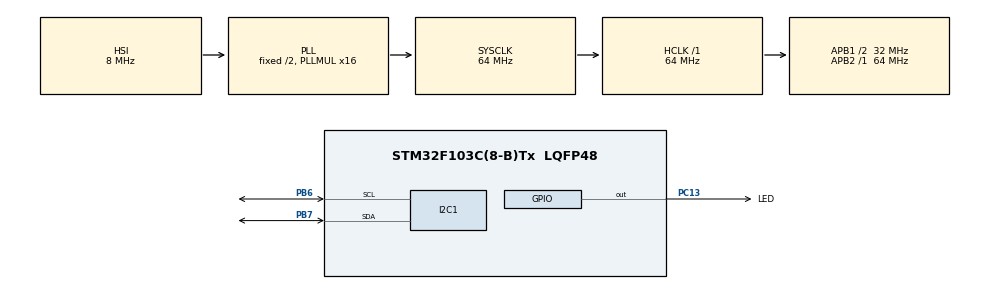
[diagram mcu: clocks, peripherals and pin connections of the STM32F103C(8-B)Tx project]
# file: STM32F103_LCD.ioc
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Mcu.Family=STM32F1
Mcu.Name=STM32F103C(8-B)Tx
Mcu.Package=LQFP48
NVIC.PriorityGroup=NVIC_PRIORITYGROUP_4
PA13.Mode=Trace_Asynchronous_SW
PA13.Signal=SYS_JTMS-SWDIO
PA14.Mode=Trace_Asynchronous_SW
PA14.Signal=SYS_JTCK-SWCLK
PB3.Mode=Trace_Asynchronous_SW
PB3.Signal=SYS_JTDO-TRACESWO
PB6.Mode=I2C
PB6.Signal=I2C1_SCL
PB7.Mode=I2C
PB7.Signal=I2C1_SDA
PC13-TAMPER-RTC.GPIO_Label=LED
PC13-TAMPER-RTC.Signal=GPIO_Output
ProjectManager.HeapSize=0x200
ProjectManager.StackSize=0x400
ProjectManager.TargetToolchain=STM32CubeIDE
RCC.AHBFreq_Value=64000000
RCC.APB1CLKDivider=RCC_HCLK_DIV2
RCC.APB1Freq_Value=32000000
RCC.APB1TimFreq_Value=64000000
RCC.APB2Freq_Value=64000000
RCC.APB2TimFreq_Value=64000000
RCC.HCLKFreq_Value=64000000
RCC.PLLMUL=RCC_PLL_MUL16
RCC.SYSCLKFreq_VALUE=64000000
RCC.SYSCLKSource=RCC_SYSCLKSOURCE_PLLCLK
RCC.USBFreq_Value=64000000
TIM3.Period=0xFFFF
TIM3.Prescaler=63
VP_TIM3_VS_ClockSourceINT.Mode=Internal
board=custom

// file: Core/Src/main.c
/* USER CODE BEGIN Header */
/**
  ******************************************************************************
  * @file           : main.c
  * @brief          : Main program body
  ******************************************************************************
  * @attention
  *
  * <h2><center>&copy; Copyright (c) 2021 STMicroelectronics.
  * All rights reserved.</center></h2>
  *
  * This software component is licensed by ST under BSD 3-Clause license,
  * the "License"; You may not use this file except in compliance with the
  * License. You may obtain a copy of the License at:
  *                        opensource.org/licenses/BSD-3-Clause
  *
  ******************************************************************************
  */
/* USER CODE END Header */
#include "main.h"
#include "i2c.h"
#include "tim.h"
#include "gpio.h"

/* USER CODE BEGIN Includes */
#include "LCD_HD44780_I2C.h"
/* USER CODE END Includes */

void SystemClock_Config(void);

int main(void)
{

  /* MCU Configuration--------------------------------------------------------*/

  /* Reset of all peripherals, Initializes the Flash interface and the Systick. */
  HAL_Init();

  /* Configure the system clock */
  SystemClock_Config();

  /* Initialize all configured peripherals */
  MX_GPIO_Init();
  MX_I2C1_Init();
  MX_TIM3_Init();
  /* USER CODE BEGIN 2 */
  HAL_TIM_Base_Start(&htim3);
  LCD_Init(&hi2c1);

  HAL_GPIO_WritePin(LED_GPIO_Port, LED_Pin, 1);
  	  // Measurement start
  	  LCD_Cls();
  	  LCD_Locate(0,0);
  	  LCD_String(" STM32 + HD44780");
  	  LCD_Locate(0,1);
  	  LCD_String("www.msalamon.pl ");
  	  // Measurement end
  	  HAL_GPIO_WritePin(LED_GPIO_Port, LED_Pin, 0);
  	  HAL_Delay(500);
  /* USER CODE END 2 */

  /* Infinite loop */
  while (1)
  {

  }
}

void SystemClock_Config(void)
{
  RCC_OscInitTypeDef RCC_OscInitStruct = {0};
  RCC_ClkInitTypeDef RCC_ClkInitStruct = {0};

  /** Initializes the RCC Oscillators according to the specified parameters
  * in the RCC_OscInitTypeDef structure.
  */
  RCC_OscInitStruct.OscillatorType = RCC_OSCILLATORTYPE_HSI;
  RCC_OscInitStruct.HSIState = RCC_HSI_ON;
  RCC_OscInitStruct.HSICalibrationValue = RCC_HSICALIBRATION_DEFAULT;
  RCC_OscInitStruct.PLL.PLLState = RCC_PLL_ON;
  RCC_OscInitStruct.PLL.PLLSource = RCC_PLLSOURCE_HSI_DIV2;
  RCC_OscInitStruct.PLL.PLLMUL = RCC_PLL_MUL16;
  if (HAL_RCC_OscConfig(&RCC_OscInitStruct) != HAL_OK)
  {
    Error_Handler();
  }
  /** Initializes the CPU, AHB and APB buses clocks
  */
  RCC_ClkInitStruct.ClockType = RCC_CLOCKTYPE_HCLK|RCC_CLOCKTYPE_SYSCLK
                              |RCC_CLOCKTYPE_PCLK1|RCC_CLOCKTYPE_PCLK2;
  RCC_ClkInitStruct.SYSCLKSource = RCC_SYSCLKSOURCE_PLLCLK;
  RCC_ClkInitStruct.AHBCLKDivider = RCC_SYSCLK_DIV1;
  RCC_ClkInitStruct.APB1CLKDivider = RCC_HCLK_DIV2;
  RCC_ClkInitStruct.APB2CLKDivider = RCC_HCLK_DIV1;

  if (HAL_RCC_ClockConfig(&RCC_ClkInitStruct, FLASH_LATENCY_2) != HAL_OK)
  {
    Error_Handler();
  }
}

void Error_Handler(void)
{
  __disable_irq();
  while (1)
  {
  }
}

/************************ (C) COPYRIGHT STMicroelectronics *****END OF FILE****/
